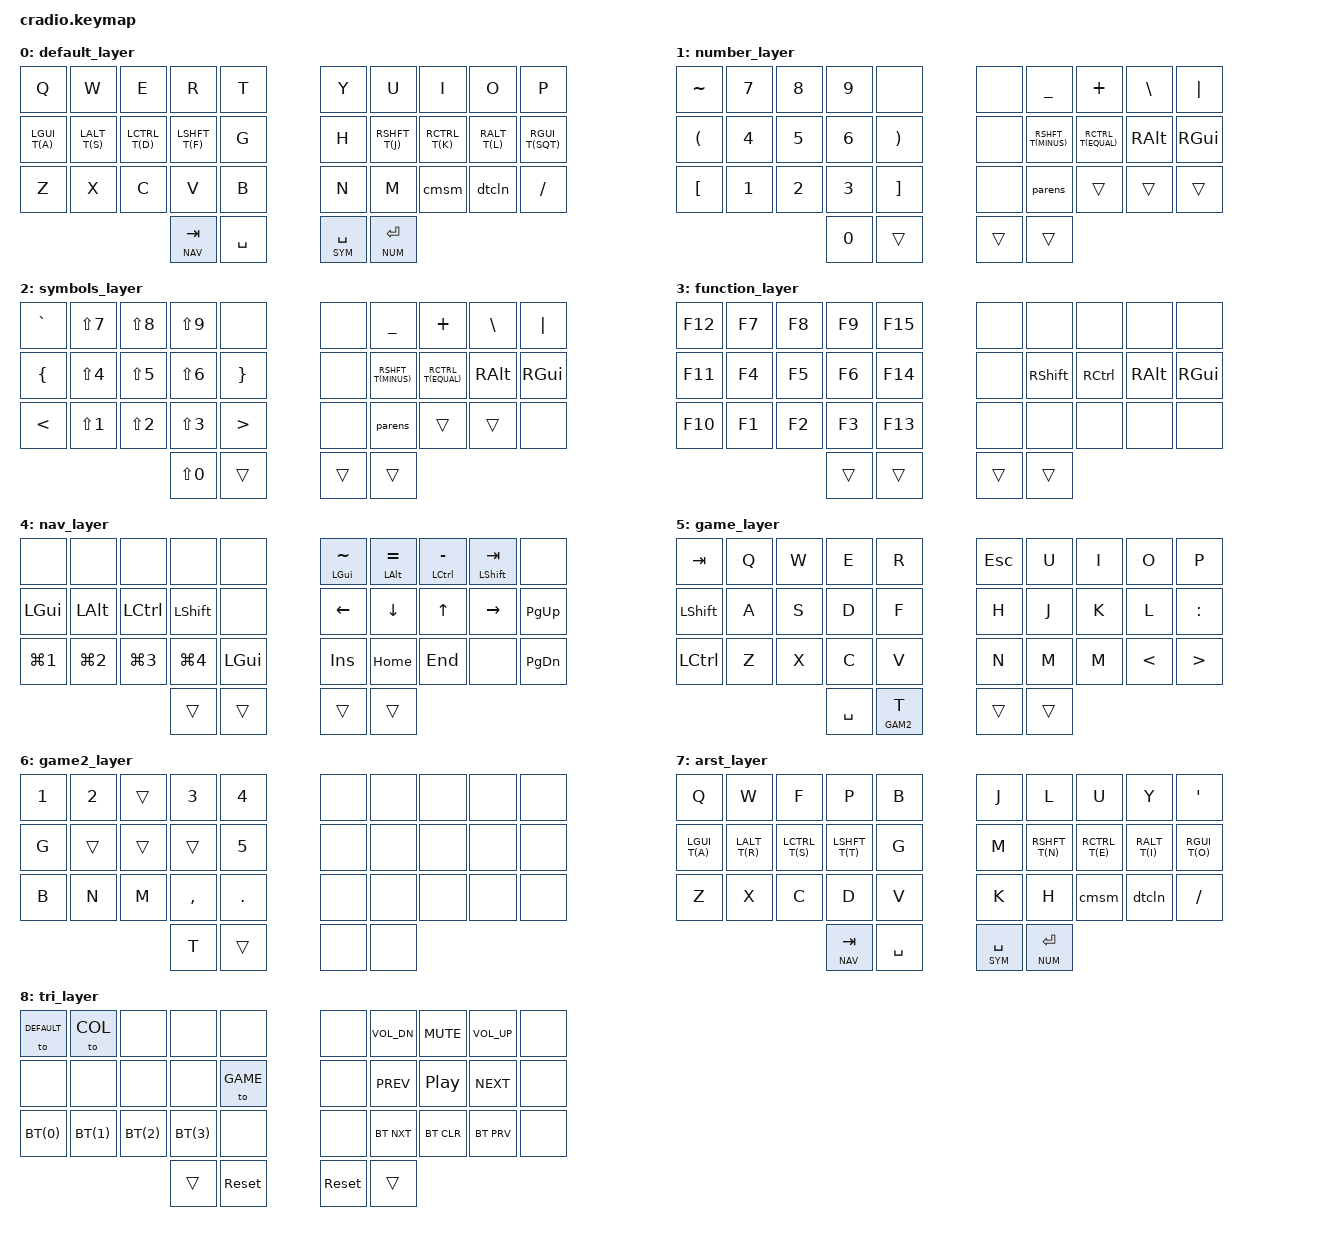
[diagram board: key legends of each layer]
#include <behaviors.dtsi>
#include <dt-bindings/zmk/keys.h>
#include <dt-bindings/zmk/bt.h>

// Some easier keycode defines
#define MUL   KP_MULTIPLY
#define DIV   KP_DIVIDE

// define combos
#define COMBO(NAME, BINDINGS, LAYERS, KEYPOS) \
  combo_##NAME { \
    timeout-ms = <50>; \
    bindings = <BINDINGS>; \
    key-positions = <KEYPOS>; \
    layers = <LAYERS>; \
  };

#define LT_B(NAME) \
  lt_##NAME: layer_tap_##NAME { \
    compatible = "zmk,behavior-hold-tap"; \
    label = "LAYER_TAP_<NAME>"; \
    #binding-cells = <2>; \
    bindings = <&mo>, <&key_repeat>; \
    tapping-term-ms = <200>; \
};

// define layers
#define DEFAULT 0
#define NUM     1
#define SYM     2
#define FUN     3
#define NAV     4
#define GAME    5
#define GAM2    6
#define COL     7
#define TRI     8

#define MODS DEFAULT COL SYM NUM FUN

// define BT MACRO
#define BT(x) &bt BT_SEL x

// Home row mods macro
#define HRMR(k1,k2,k3,k4) &ht RGUI  k1 &ht RSHFT k2  &ht RCTRL  k3  &ht RALT  k4
#define HRSCL(k1,k2) &ht LCTRL k1  &ht LSHFT k2
#define HRSCR(k1,k2) &ht RSHFT k1 &ht RCTRL k2
#define ALTTAB LA(TAB)
#define ALTGRV LA(GRAVE)

#define LGUI_T(k)  &ht LGUI k
#define LALT_T(k)  &ht LALT k
#define LSHFT_T(k) &ht LSHFT k
#define LCTRL_T(k) &ht LCTRL k
#define RGUI_T(k)  &ht RGUI k
#define RALT_T(k)  &ht RALT k
#define RSHFT_T(k) &ht RSHFT k
#define RCTRL_T(k) &ht RCTRL k




/ {
    combos {
        compatible = "zmk,combos";
        COMBO(escape, &kp ESC, MODS, 2 3)
        COMBO(backspace, &kp BSPC, MODS, 6 7)
        COMBO(delete, &kp DEL, MODS, 7 8)

        COMBO(tab, &kp TAB, MODS, 22 23)
        COMBO(return, &kp RETURN, MODS, 26 27)
        // COMBO(repeat, &repeatkey, MODS, 27 28)

        // COMBO(left_alt, &kp LALT, MODS, 11 21)
        // COMBO(left_shift, &kp LSFT, MODS, 12 22)
        // COMBO(left_ctrl, &kp LCTRL, MODS, 13 23)
        // COMBO(left_gui, &kp LGUI, MODS, 14 24)
        //
        // COMBO(right_gui, &kp RGUI, MODS, 15 25)
        // COMBO(right_ctrl, &kp RCTRL, MODS, 16 26)
        // COMBO(right_shift, &kp RSHFT, MODS, 17 27)
        // COMBO(right_alt, &kp RALT, MODS, 18 28)
    };

    behaviors {

        td: tapdance {
            compatible = "zmk,behavior-hold-tap";
            label = "TAPDANCE";
            #binding-cells = <2>;
            tapping-term-ms = <150>;
            quick_tap_ms = <0>;
            flavor = "tap-preferred";
            bindings = <&kp>, <&kp>;
        };

        ht: hold_tap {
            label = "hold_tap";
            compatible = "zmk,behavior-hold-tap";
            #binding-cells = <2>;
            flavor = "tap-preferred";
            tapping-term-ms = <200>;
            quick-tap-ms = <125>;
            // global-quick-tap;
            bindings = <&kp>, <&kp>;
        };

        gresc: grave_escape {
            label = "grave_escape";
            compatible = "zmk,behavior-mod-morph";
            #binding-cells = <0>;
            bindings = <&kp ESC>, <&kp GRAVE>;
            mods = <(MOD_LGUI|MOD_LSFT|MOD_RGUI|MOD_RSFT)>;
        };

        cmsm: comma_semicolon {
            label = "comma_semicolon";
            compatible = "zmk,behavior-mod-morph";
            #binding-cells = <0>;
            bindings = <&kp COMMA>, <&kp SEMI>;
            mods = <(MOD_LSFT|MOD_RSFT)>;
        };

        dtcln: dot_colon {
            label = "dot_colon";
            compatible = "zmk,behavior-mod-morph";
            #binding-cells = <0>;
            bindings = <&kp DOT>, <&kp COLON>;
            mods = <(MOD_LSFT|MOD_RSFT)>;
        };

        parens: parens {
            label = "parens";
            compatible = "zmk,behavior-mod-morph";
            #binding-cells = <0>;
            bindings = <&kp LPAR>, <&kp RPAR>;
            mods = <(MOD_LSFT|MOD_RSFT)>;
        };

        angles: angles {
            label = "angles";
            compatible = "zmk,behavior-mod-morph";
            #binding-cells = <0>;
            bindings = <&kp LT>, <&kp GT>;
            mods = <(MOD_LSFT|MOD_RSFT)>;
        };

        bracket: bracket {
            label = "bracket";
            compatible = "zmk,behavior-mod-morph";
            #binding-cells = <0>;
            bindings = <&kp LBKT>, <&kp RBKT>;
            mods = <(MOD_LSFT|MOD_RSFT)>;
        };
    };

    conditional_layers {
        compatible = "zmk,conditional-layers";
        tri_layer {
            if-layers = <NAV NUM>;
            then-layer = <TRI>;
        };
        function_layer {
            if-layers = <SYM NUM>;
            then-layer = <FUN>;
        };
    };

    keymap {
        compatible = "zmk,keymap";
        default_layer {
            bindings = <
            &kp Q      &kp W       &kp E       &kp R        &kp T          &kp Y           &kp U           &kp I           &kp O           &kp P
            LGUI_T(A)  LALT_T(S)   LCTRL_T(D)  LSHFT_T(F)   &kp G          &kp H           RSHFT_T(J)      RCTRL_T(K)      RALT_T(L)       RGUI_T(SQT)
            &kp Z      &kp X       &kp C       &kp V        &kp B          &kp N           &kp M           &cmsm           &dtcln          &kp FSLH
                                               &lt NAV TAB  &kp SPC        &lt SYM SPC     &lt NUM RETURN
            >;
        };

       number_layer {
            bindings = <
            &kp TILDE  &kp N7      &kp N8      &kp N9       &none          &none           &kp UNDER       &kp PLUS        &kp BSLH        &kp PIPE
            &kp LPAR   &kp N4      &kp N5      &kp N6       &kp RPAR       &none           RSHFT_T(MINUS)  RCTRL_T(EQUAL)  &kp RALT        &kp RGUI
            &kp LBKT   &kp N1      &kp N2      &kp N3       &kp RBKT       &none           &parens         &trans          &trans          &trans
                                               &kp N0       &trans         &trans          &trans
            >;
       };

       symbols_layer {
            bindings = <
            &kp GRAVE  &kp LS(N7)  &kp LS(N8)  &kp LS(N9)   &none          &none           &kp UNDER       &kp PLUS        &kp BSLH        &kp PIPE
            &kp LBRC   &kp LS(N4)  &kp LS(N5)  &kp LS(N6)   &kp RBRC       &none           RSHFT_T(MINUS)  RCTRL_T(EQUAL)  &kp RALT        &kp RGUI
            &kp LT     &kp LS(N1)  &kp LS(N2)  &kp LS(N3)   &kp GT         &none           &parens         &trans          &trans          &none
                                               &kp LS(N0)   &trans         &trans          &trans
            >;
       };


       function_layer {
            bindings = <
            &kp F12    &kp F7      &kp F8      &kp F9       &kp F15        &none           &none           &none            &none          &none
            &kp F11    &kp F4      &kp F5      &kp F6       &kp F14        &none           &kp RSHFT       &kp RCTL         &kp RALT       &kp RGUI
            &kp F10    &kp F1      &kp F2      &kp F3       &kp F13        &none           &none           &none            &none          &none
                                               &trans       &trans         &trans          &trans
            >;
       };

       nav_layer {
            bindings = <
            &none      &none       &none       &none        &none          &ht LGUI TILDE  &ht LALT EQUAL  &ht LCTL MINUS   &ht LSHFT TAB  &none
            &kp LGUI   &kp LALT    &kp LCTL    &kp LSHFT    &none          &kp LEFT        &kp DOWN        &kp UP           &kp RIGHT      &kp PG_UP
            &kp LG(N1) &kp LG(N2)  &kp LG(N3)  &kp LG(N4)   &kp LGUI       &kp INS         &kp HOME        &kp END          &none          &kp PG_DN
                                               &trans       &trans         &trans          &trans
            >;
       };

       game_layer {
            bindings = <
            &kp TAB    &kp Q        &kp W     &kp E         &kp R          &kp ESC         &kp U           &kp I            &kp O          &kp P
            &kp LSHFT  &kp A        &kp S     &kp D         &kp F          &kp H           &kp J           &kp K            &kp L          &kp COLON
            &kp LCTL   &kp Z        &kp X     &kp C         &kp V          &kp N           &kp M           &kp M            &kp LT         &kp GT
                                              &kp SPACE     &lt GAM2 T     &trans          &trans
            >;
       };

       game2_layer {
            bindings = <
            &kp N1     &kp N2       &trans    &kp N3        &kp N4         &none           &none           &none            &none          &none
            &kp G      &trans       &trans    &trans        &kp N5         &none           &none           &none            &none          &none
            &kp B      &kp N        &kp M     &kp COMMA     &kp DOT        &none           &none           &none            &none          &none
                                              &kp T         &trans         &none           &none
            >;
       };

       arst_layer {
           bindings = <
           &kp Q      &kp W       &kp F       &kp P        &kp B          &kp J           &kp L           &kp U           &kp Y           &kp SQT
           LGUI_T(A)  LALT_T(R)   LCTRL_T(S)  LSHFT_T(T)   &kp G          &kp M           RSHFT_T(N)      RCTRL_T(E)      RALT_T(I)       RGUI_T(O)
           &kp Z      &kp X       &kp C       &kp D        &kp V          &kp K           &kp H           &cmsm           &dtcln          &kp FSLH
                                              &lt NAV TAB  &kp SPC        &lt SYM SPC     &lt NUM RETURN
           >;
       };

       tri_layer {
            bindings = <
            &to DEFAULT &to COL     &none        &none      &none          &none           &kp C_VOL_DN    &kp C_MUTE       &kp C_VOL_UP   &none
            &none       &none       &none        &none      &to GAME       &none           &kp C_PREV      &kp C_PP         &kp C_NEXT     &none
            BT(0)       BT(1)       BT(2)        BT(3)      &none          &none           &bt BT_NXT      &bt BT_CLR       &bt BT_PRV     &none
                                                &trans     &sys_reset      &sys_reset      &trans
            >;
       };
    };
};



